# S1C31D50 register map
Vendor: Epson; Series: S1C31D50; File version: 1.00
CPU: CM0PLUS r0p1, little endian, MPU, no FPU, VTOR, 2 interrupt priority bits
Registers are 16-bit, read-write, reset 0x0 unless marked. A register's access mark holds for its fields unless they carry their own. Offsets are from the block's base; [hi:lo] are bit positions; lines under a group give offsets from that group; {n}, {i} and the like mark numbered series; 'fields as' and 'values as' point back to an identical list.

## PPORT — I/O P0-9,PA,PD Ports control
Base 0x00200200
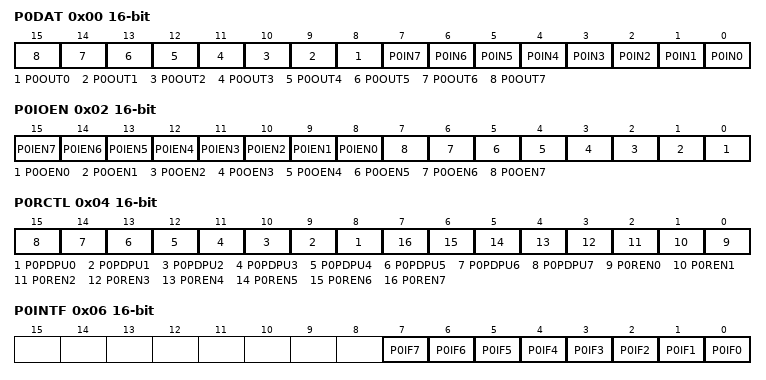
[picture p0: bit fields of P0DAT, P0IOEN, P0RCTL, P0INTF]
0x00 P0DAT — P0 Port Data Register
  [n+8] P0OUT{n} (n=0..7) — P{n:02} port output data
    0=L (Output low level from the port pin); 1=H (Output high level from the port pin)
  [n] P0IN{n} ro (n=0..7) — P{n:02} port input data
    0=L (Port pin = Low level); 1=H (Port pin = High level)
0x02 P0IOEN — P0 Port Enable Register
  [n+8] P0IEN{n} (n=0..7) — P{n:02} port input enable control
    0=DISABLE (Disable (Input data is fixed at 0)); 1=ENABLE (Enable (The port pin status is input))
  [n] P0OEN{n} (n=0..7) — P{n:02} port output enable control
    0=DISABLE (Disable (The port is placed into Hi-Z)); 1=ENABLE (Enable (Data is output from the port pin))
0x04 P0RCTL — P0 Port Pull-up/down Control Register
  [n+8] P0PDPU{n} (n=0..7) — P{n:02} port input resistor select
    0=DOWN (Pull-down resistor); 1=UP (Pull-up resistor)
  [n] P0REN{n} (n=0..7) — P{n:02} port input resistor enable
    0=DISABLE (Disable (No pull-up/down control is performed)); 1=ENABLE (Enable (The built-in pull-up/down resistor is used))
0x06 P0INTF — P0 Port Interrupt Flag Register
  [all] fields
    0=NOT_OCCURED (No cause of interrupt occurred); 1=OCCURED (Cause of interrupt occurred)
  [n] P0IF{n} write-1-clears (n=0..7) — P{n:02} port interrupt flag
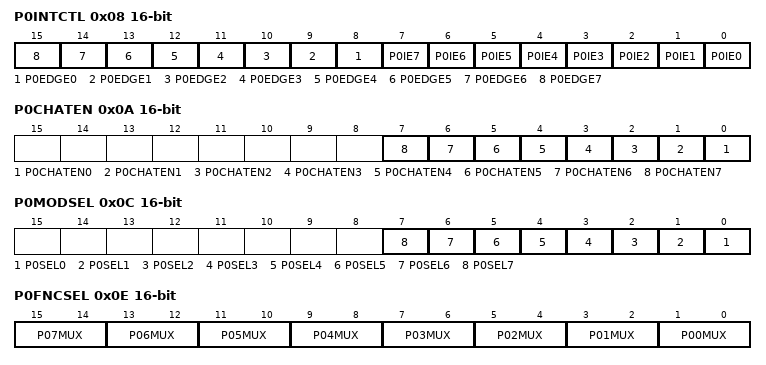
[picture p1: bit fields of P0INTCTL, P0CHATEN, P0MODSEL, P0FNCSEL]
0x08 P0INTCTL — P0 Port Interrupt Control Register
  [n+8] P0EDGE{n} (n=0..7) — P{n:02} port interrupt trigger edge select
    0=POSEDGE (An interrupt will occur at a rising edge); 1=NEGEDGE (An interrupt will occur at a falling edge)
  [n] P0IE{n} (n=0..7) — P{n:02} port interrupt enable
    0=DISABLE (Disable interrupt); 1=ENABLE (Enable interrupt)
0x0A P0CHATEN — P0 Port Chattering Filter Enable Register
  [all] fields
    0=DISABLE (Disable (The chattering filter is bypassed)); 1=ENABLE (Enable (The chattering filter is used))
  [n] P0CHATEN{n} (n=0..7) — P{n:02} chatter less enable
0x0C P0MODSEL — P0 Port Mode Select Register
  [all] fields
    0=PPORT (Use GPIO function); 1=OTHER (Use peripheral I/O function)
  [n] P0SEL{n} (n=0..7) — P{n:02} port mode select
0x0E P0FNCSEL — P0 Port Function Select Register
  [all] fields
    0=FUNC_0 (Function 0); 1=FUNC_1 (Function 1); 2=AIN (Analogue function); 3=LCD_DR (LCD drive function)
  [2n+1:2n] P{n:02}MUX (n=0..7) — P{n:02} port function select
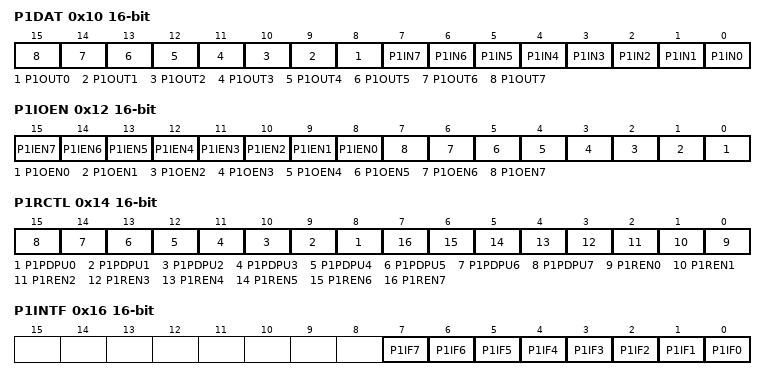
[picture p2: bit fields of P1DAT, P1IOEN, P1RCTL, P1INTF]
0x10 P1DAT — P1 Port Data Register
  [n+8] P1OUT{n} (n=0..7) — P{n+10} port output data
    values as P0DAT.P0OUT0
  [n] P1IN{n} ro (n=0..7) — P{n+10} port input data
    0=L (Port pin = Low level); 1=H (Port pin = High level)
0x12 P1IOEN — P1 Port Enable Register
  [n+8] P1IEN{n} (n=0..7) — P{n+10} port input enable control
    values as P0IOEN.P0IEN0
  [n] P1OEN{n} (n=0..7) — P{n+10} port output enable control
    values as P0IOEN.P0OEN0
0x14 P1RCTL — P1 Port Pull-up/down Control Register
  [n+8] P1PDPU{n} (n=0..7) — P{n+10} port input resistor select
    0=DOWN (Pull-down resistor); 1=UP (Pull-up resistor)
  [n] P1REN{n} (n=0..7) — P{n+10} port input resistor enable
    values as P0RCTL.P0REN0
0x16 P1INTF — P1 Port Interrupt Flag Register
  [all] fields
    values as the fields of P0INTF
  [n] P1IF{n} write-1-clears (n=0..7) — P{n+10} port interrupt flag
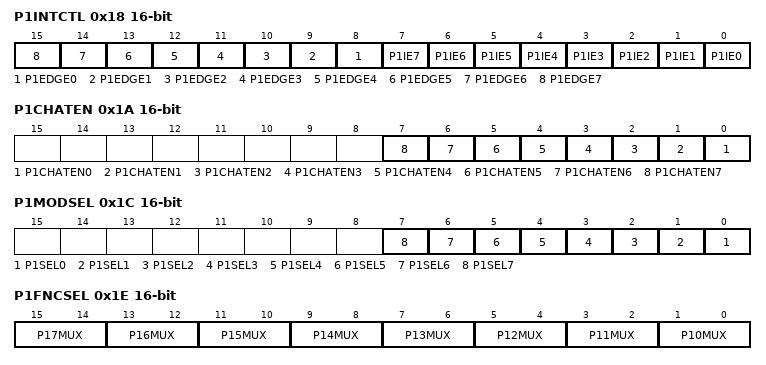
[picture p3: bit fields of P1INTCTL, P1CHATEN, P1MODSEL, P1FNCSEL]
0x18 P1INTCTL — P1 Port Interrupt Control Register
  [n+8] P1EDGE{n} (n=0..7) — P{n+10} port interrupt trigger edge select
    values as P0INTCTL.P0EDGE0
  [n] P1IE{n} (n=0..7) — P{n+10} port interrupt enable
    0=DISABLE (Disable interrupt); 1=ENABLE (Enable interrupt)
0x1A P1CHATEN — P1 Port Chattering Filter Enable Register
  [all] fields
    values as the fields of P0CHATEN
  [n] P1CHATEN{n} (n=0..7) — P{n+10} chatter less enable
0x1C P1MODSEL — P1 Port Mode Select Register
  [all] fields
    values as the fields of P0MODSEL
  [n] P1SEL{n} (n=0..7) — P{n+10} port mode select
0x1E P1FNCSEL — P1 Port Function Select Register
  [all] fields
    values as the fields of P0FNCSEL
  [2n-19:2n-20] P{n}MUX (n=10..17) — P{n} port function select
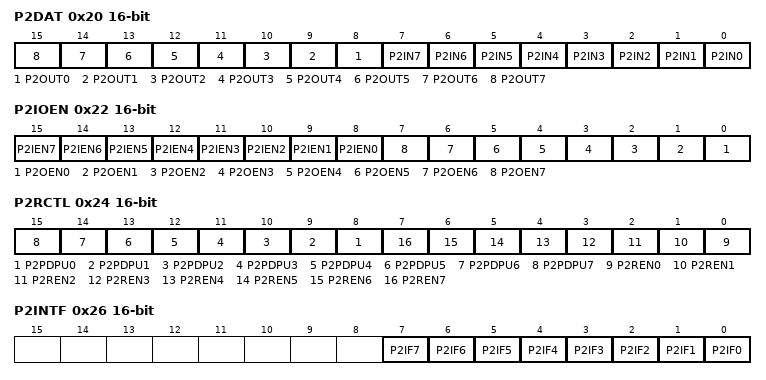
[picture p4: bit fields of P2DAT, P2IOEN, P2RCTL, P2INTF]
0x20 P2DAT — P2 Port Data Register
  [n+8] P2OUT{n} (n=0..7) — P{n+20} port output data
    values as P0DAT.P0OUT0
  [n] P2IN{n} ro (n=0..7) — P{n+20} port input data
    0=L (Port pin = Low level); 1=H (Port pin = High level)
0x22 P2IOEN — P2 Port Enable Register
  [n+8] P2IEN{n} (n=0..7) — P{n+20} port input enable control
    values as P0IOEN.P0IEN0
  [n] P2OEN{n} (n=0..7) — P{n+20} port output enable control
    values as P0IOEN.P0OEN0
0x24 P2RCTL — P2 Port Pull-up/down Control Register
  [n+8] P2PDPU{n} (n=0..7) — P{n+20} port input resistor select
    0=DOWN (Pull-down resistor); 1=UP (Pull-up resistor)
  [n] P2REN{n} (n=0..7) — P{n+20} port input resistor enable
    values as P0RCTL.P0REN0
0x26 P2INTF — P2 Port Interrupt Flag Register
  [all] fields
    values as the fields of P0INTF
  [n] P2IF{n} write-1-clears (n=0..7) — P{n+20} port interrupt flag
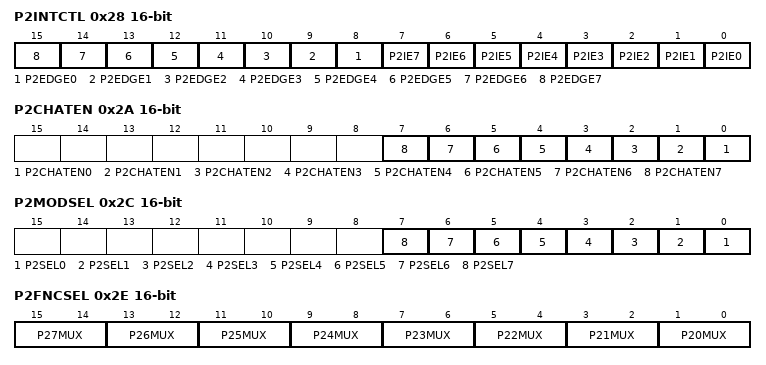
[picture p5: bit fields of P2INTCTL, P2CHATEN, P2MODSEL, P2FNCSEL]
0x28 P2INTCTL — P2 Port Interrupt Control Register
  [n+8] P2EDGE{n} (n=0..7) — P{n+20} port interrupt trigger edge select
    values as P0INTCTL.P0EDGE0
  [n] P2IE{n} (n=0..7) — P{n+20} port interrupt enable
    0=DISABLE (Disable interrupt); 1=ENABLE (Enable interrupt)
0x2A P2CHATEN — P2 Port Chattering Filter Enable Register
  [all] fields
    values as the fields of P0CHATEN
  [n] P2CHATEN{n} (n=0..7) — P{n+20} chatter less enable
0x2C P2MODSEL — P2 Port Mode Select Register
  [all] fields
    values as the fields of P0MODSEL
  [n] P2SEL{n} (n=0..7) — P{n+20} port mode select
0x2E P2FNCSEL — P2 Port Function Select Register
  [all] fields
    values as the fields of P0FNCSEL
  [2n-39:2n-40] P{n}MUX (n=20..27) — P{n} port function select
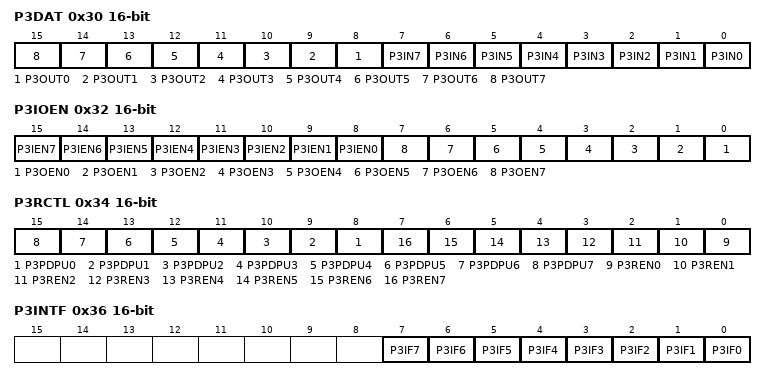
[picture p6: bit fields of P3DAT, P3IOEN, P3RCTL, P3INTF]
0x30 P3DAT — P3 Port Data Register
  [n+8] P3OUT{n} (n=0..7) — P{n+30} port output data
    values as P0DAT.P0OUT0
  [n] P3IN{n} ro (n=0..7) — P{n+30} port input data
    0=L (Port pin = Low level); 1=H (Port pin = High level)
0x32 P3IOEN — P3 Port Enable Register
  [n+8] P3IEN{n} (n=0..7) — P{n+30} port input enable control
    values as P0IOEN.P0IEN0
  [n] P3OEN{n} (n=0..7) — P{n+30} port output enable control
    values as P0IOEN.P0OEN0
0x34 P3RCTL — P3 Port Pull-up/down Control Register
  [n+8] P3PDPU{n} (n=0..7) — P{n+30} port input resistor select
    0=DOWN (Pull-down resistor); 1=UP (Pull-up resistor)
  [n] P3REN{n} (n=0..7) — P{n+30} port input resister enable
    values as P0RCTL.P0REN0
0x36 P3INTF — P3 Port Interrupt Flag Register
  [all] fields
    values as the fields of P0INTF
  [n] P3IF{n} write-1-clears (n=0..7) — P{n+30} port interrupt flag
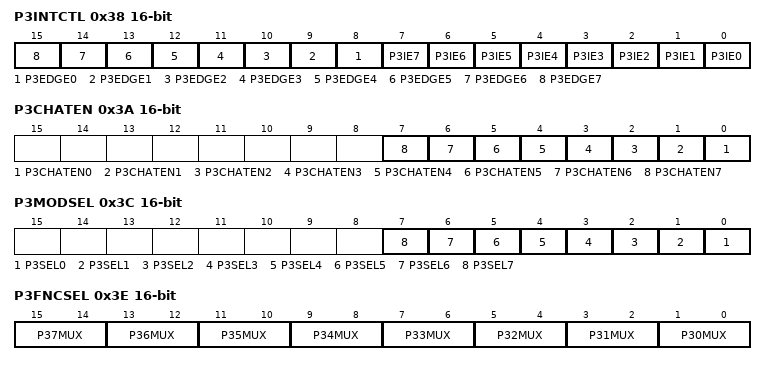
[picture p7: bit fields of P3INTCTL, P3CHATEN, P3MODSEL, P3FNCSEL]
0x38 P3INTCTL — P3 Port Interrupt Control Register
  [n+8] P3EDGE{n} (n=0..7) — P{n+30} port interrupt trigger edge select
    values as P0INTCTL.P0EDGE0
  [n] P3IE{n} (n=0..7) — P{n+30} port interrupt enable
    0=DISABLE (Disable interrupt); 1=ENABLE (Enable interrupt)
0x3A P3CHATEN — P3 Port Chattering Filter Enable Register
  [all] fields
    values as the fields of P0CHATEN
  [n] P3CHATEN{n} (n=0..7) — P{n+30} chatter less enable
0x3C P3MODSEL — P3 Port Mode Select Register
  [all] fields
    values as the fields of P0MODSEL
  [n] P3SEL{n} (n=0..7) — P{n+30} port mode select
0x3E P3FNCSEL — P3 Port Function Select Register
  [all] fields
    values as the fields of P0FNCSEL
  [2n-59:2n-60] P{n}MUX (n=30..37) — P{n} port function select
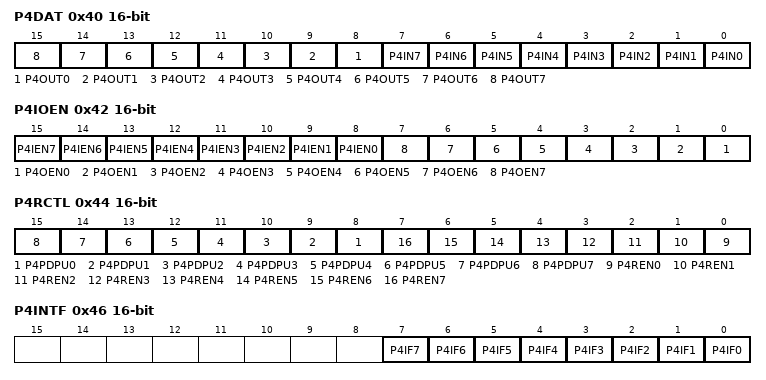
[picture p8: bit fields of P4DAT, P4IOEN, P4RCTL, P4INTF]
0x40 P4DAT — P4 Port Data Register
  [n+8] P4OUT{n} (n=0..7) — P{n+40} port output data
    values as P0DAT.P0OUT0
  [n] P4IN{n} ro (n=0..7) — P{n+40} port input data
    0=L (Port pin = Low level); 1=H (Port pin = High level)
0x42 P4IOEN — P4 Port Enable Register
  [n+8] P4IEN{n} (n=0..7) — P{n+40} port input enable control
    values as P0IOEN.P0IEN0
  [n] P4OEN{n} (n=0..7) — P{n+40} port output enable control
    values as P0IOEN.P0OEN0
0x44 P4RCTL — P4 Port Pull-up/down Control Register
  [n+8] P4PDPU{n} (n=0..7) — P{n+40} port input resistor select
    0=DOWN (Pull-down resistor); 1=UP (Pull-up resistor)
  [n] P4REN{n} (n=0..7) — P{n+40} port input resistor enable
    values as P0RCTL.P0REN0
0x46 P4INTF — P4 Port interrupt Flag Register
  [all] fields
    values as the fields of P0INTF
  [n] P4IF{n} write-1-clears (n=0..7) — P{n+40} port interrupt flag
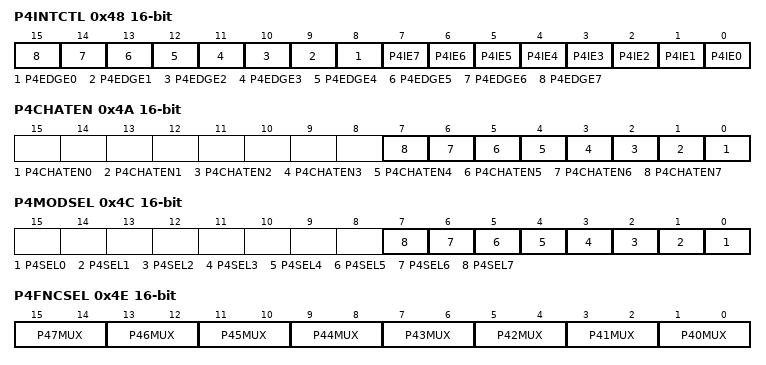
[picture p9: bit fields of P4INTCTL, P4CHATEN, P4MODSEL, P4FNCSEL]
0x48 P4INTCTL — P4 Port Interrupt Control Register
  [n+8] P4EDGE{n} (n=0..7) — P{n+40} port interrupt trigger edge select
    values as P0INTCTL.P0EDGE0
  [n] P4IE{n} (n=0..7) — P{n+40} port interrupt enable
    0=DISABLE (Disable interrupt); 1=ENABLE (Enable interrupt)
0x4A P4CHATEN — P4 Port Chattering Filter Enable Register
  [all] fields
    values as the fields of P0CHATEN
  [n] P4CHATEN{n} (n=0..7) — P{n+40} chatter less enable
0x4C P4MODSEL — P4 Port Mode Select Register
  [all] fields
    values as the fields of P0MODSEL
  [n] P4SEL{n} (n=0..7) — P{n+40} port mode select
0x4E P4FNCSEL — P4 Port Function Select Register
  [all] fields
    values as the fields of P0FNCSEL
  [2n-79:2n-80] P{n}MUX (n=40..47) — P{n} port function select
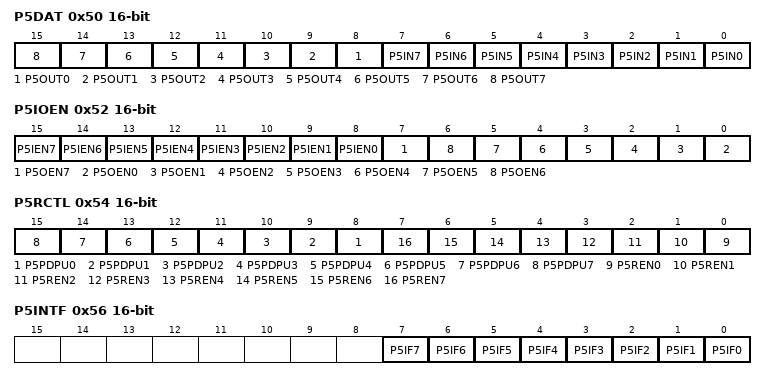
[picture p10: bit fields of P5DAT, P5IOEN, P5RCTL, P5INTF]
0x50 P5DAT — P5 Port Data Register
  [n+8] P5OUT{n} (n=0..7) — P{n+50} port output data
    values as P0DAT.P0OUT0
  [n] P5IN{n} ro (n=0..7) — P{n+50} port input data
    0=L (Port pin = Low level); 1=H (Port pin = High level)
0x52 P5IOEN — P5 Port Enable Register
  [n+8] P5IEN{n} (n=0..7) — P{n+50} port input enable control
    values as P0IOEN.P0IEN0
  [7] P5OEN7 — P57port output enable control
    values as P0IOEN.P0OEN0
  [n] P5OEN{n} (n=0..6) — P{n+50} port output enable control
    values as P0IOEN.P0OEN0
0x54 P5RCTL — P5 Port Pull-up/down Control Register
  [n+8] P5PDPU{n} (n=0..7) — P{n+50} port input resistor select
    0=DOWN (Pull-down resistor); 1=UP (Pull-up resistor)
  [n] P5REN{n} (n=0..7) — P{n+50} port input resistor enable
    values as P0RCTL.P0REN0
0x56 P5INTF — P5 Port Interrupt Flag Register
  [all] fields
    values as the fields of P0INTF
  [n] P5IF{n} write-1-clears (n=0..7) — P{n+50} port interrupt flag
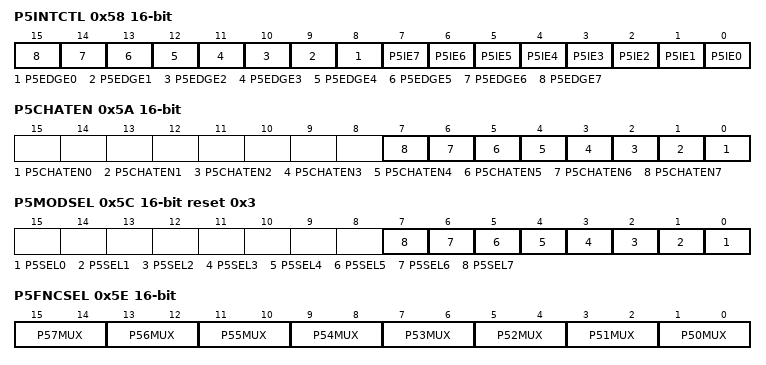
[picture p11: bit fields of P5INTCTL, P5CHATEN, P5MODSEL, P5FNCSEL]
0x58 P5INTCTL — P5 Port Interrupt Control Register
  [n+8] P5EDGE{n} (n=0..7) — P{n+50} port interrupt trigger edge select
    values as P0INTCTL.P0EDGE0
  [n] P5IE{n} (n=0..7) — P{n+50} port interrupt enable
    0=DISABLE (Disable interrupt); 1=ENABLE (Enable interrupt)
0x5A P5CHATEN — P5 Port Chattering Filter Enable Register
  [all] fields
    values as the fields of P0CHATEN
  [n] P5CHATEN{n} (n=0..7) — P{n+50} chatter less enable
0x5C P5MODSEL reset 0x3 — P5 Port Mode Select Register
  [all] fields
    values as the fields of P0MODSEL
  [n] P5SEL{n} (n=0..7) — P{n+50} port mode select
0x5E P5FNCSEL — P5 Port Function Select Register
  [all] fields
    values as the fields of P0FNCSEL
  [2n-99:2n-100] P{n}MUX (n=50..57) — P{n} port function select
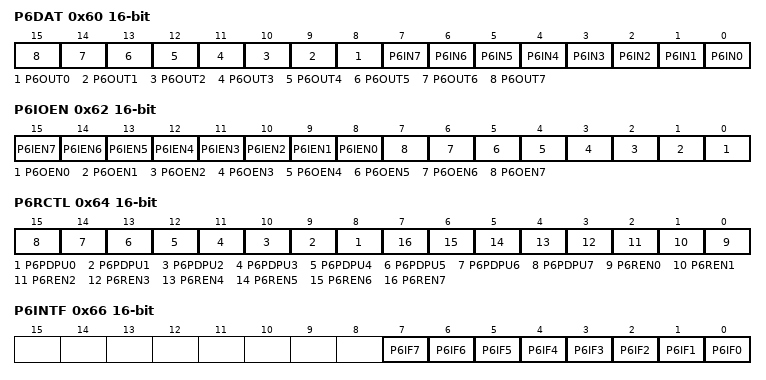
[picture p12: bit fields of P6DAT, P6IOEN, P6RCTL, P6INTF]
0x60 P6DAT — P6 Port Data Register
  [n+8] P6OUT{n} (n=0..7) — P{n+60} port output data
    values as P0DAT.P0OUT0
  [n] P6IN{n} ro (n=0..7) — P{n+60} port input data
    0=L (Port pin = Low level); 1=H (Port pin = High level)
0x62 P6IOEN — P6 Port Enable Register
  [n+8] P6IEN{n} (n=0..7) — P{n+60} port input enable control
    values as P0IOEN.P0IEN0
  [n] P6OEN{n} (n=0..7) — P{n+60} port output enable control
    values as P0IOEN.P0OEN0
0x64 P6RCTL — P6 Port Pull-up/down Control Register
  [n+8] P6PDPU{n} (n=0..7) — P{n+60} port input resistor select
    0=DOWN (Pull-down resistor); 1=UP (Pull-up resistor)
  [n] P6REN{n} (n=0..7) — P{n+60} port input resistor enable
    values as P0RCTL.P0REN0
0x66 P6INTF — P6 Port Interrupt Flag Register
  [all] fields
    values as the fields of P0INTF
  [n] P6IF{n} write-1-clears (n=0..7) — P{n+60} port interrupt flag
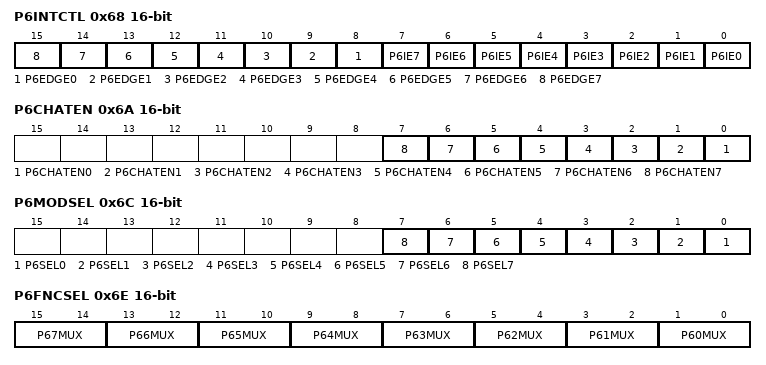
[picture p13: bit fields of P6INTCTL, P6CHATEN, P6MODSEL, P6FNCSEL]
0x68 P6INTCTL — P6 Port Interrupt Control Register
  [n+8] P6EDGE{n} (n=0..7) — P{n+60} port interrupt trigger edge select
    values as P0INTCTL.P0EDGE0
  [n] P6IE{n} (n=0..7) — P{n+60} port interrupt enable
    0=DISABLE (Disable interrupt); 1=ENABLE (Enable interrupt)
0x6A P6CHATEN — P6 Port Chattering Filter Enable Register
  [all] fields
    values as the fields of P0CHATEN
  [n] P6CHATEN{n} (n=0..7) — P{n+60} chatter less enable
0x6C P6MODSEL — P6 Port Mode Select Register
  [all] fields
    values as the fields of P0MODSEL
  [n] P6SEL{n} (n=0..7) — P{n+60} port mode select
0x6E P6FNCSEL — P6 Port Function Select Register
  [all] fields
    values as the fields of P0FNCSEL
  [2n-119:2n-120] P{n}MUX (n=60..67) — P{n} port function select
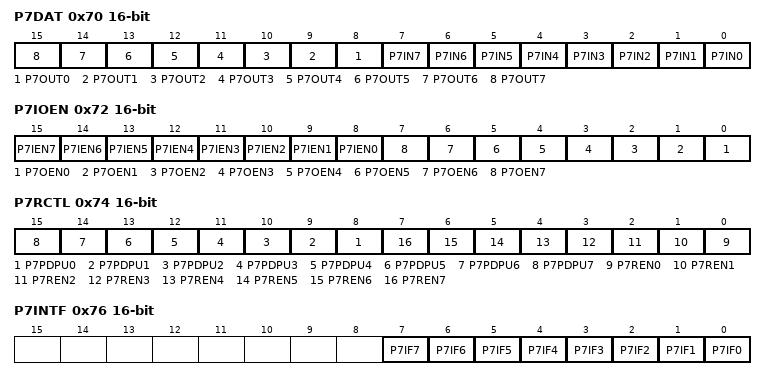
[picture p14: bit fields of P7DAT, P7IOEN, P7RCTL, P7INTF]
0x70 P7DAT — P7 Port Data Register
  [n+8] P7OUT{n} (n=0..7) — P{n+70} port output data
    values as P0DAT.P0OUT0
  [n] P7IN{n} ro (n=0..7) — P{n+70} port input data
    0=L (Port pin = Low level); 1=H (Port pin = High level)
0x72 P7IOEN — P7 Port Enable Register
  [n+8] P7IEN{n} (n=0..7) — P{n+70} port input enable control
    values as P0IOEN.P0IEN0
  [n] P7OEN{n} (n=0..7) — P{n+70} port output enable control
    values as P0IOEN.P0OEN0
0x74 P7RCTL — P7 Port Pull-up/down Control Register
  [n+8] P7PDPU{n} (n=0..7) — P{n+70} port input resistor select
    0=DOWN (Pull-down resistor); 1=UP (Pull-up resistor)
  [n] P7REN{n} (n=0..7) — P{n+70} port input resistor enable
    values as P0RCTL.P0REN0
0x76 P7INTF — P7 Port Interrupt Flag Register
  [all] fields
    values as the fields of P0INTF
  [n] P7IF{n} write-1-clears (n=0..7) — P{n+70} port interrupt flag
0x78 P7INTCTL — P7 Port Interrupt Control Register
  [n+8] P7EDGE{n} (n=0..7) — P{n+70} port interrupt trigger edge select
    values as P0INTCTL.P0EDGE0
  [n] P7IE{n} (n=0..7) — P{n+70} port interrupt enable
    0=DISABLE (Disable interrupt); 1=ENABLE (Enable interrupt)
0x7A P7CHATEN — P7 Port Chattering Filter Enable Register
  [all] fields
    values as the fields of P0CHATEN
  [n] P7CHATEN{n} (n=0..7) — P{n+70} chatter less enable
0x7C P7MODSEL — P7 Port Mode Select Register
  [all] fields
    values as the fields of P0MODSEL
  [n] P7SEL{n} (n=0..7) — P{n+70} port mode select
0x7E P7FNCSEL — P7 Port Function Select Register
  [all] fields
    values as the fields of P0FNCSEL
  [2n-139:2n-140] P{n}MUX (n=70..77) — P{n} port function select
0x80 P8DAT — P8 Port Data Register
  [n+8] P8OUT{n} (n=0..7) — P{n+80} port output data
    values as P0DAT.P0OUT0
  [n] P8IN{n} ro (n=0..7) — P{n+80} port input data
    0=L (Port pin = Low level); 1=H (Port pin = High level)
0x82 P8IOEN — P8 Port Enable Register
  [n+8] P8IEN{n} (n=0..7) — P{n+80} port input enable control
    values as P0IOEN.P0IEN0
  [n] P8OEN{n} (n=0..7) — P{n+80} port output enable control
    values as P0IOEN.P0OEN0
0x84 P8RCTL — P8 Port Pull-up/down Control Register
  [n+8] P8PDPU{n} (n=0..7) — P{n+80} port input resistor select
    0=DOWN (Pull-down resistor); 1=UP (Pull-up resistor)
  [n] P8REN{n} (n=0..7) — P{n+80} port input resistor enable
    values as P0RCTL.P0REN0
0x86 P8INTF — P8 Port Interrupt Flag Register
  [all] fields
    values as the fields of P0INTF
  [n] P8IF{n} write-1-clears (n=0..7) — P{n+80} port interrupt flag
0x88 P8INTCTL — P8 Port Interrupt Control Register
  [n+8] P8EDGE{n} (n=0..7) — P{n+80} port interrupt trigger edge select
    values as P0INTCTL.P0EDGE0
  [n] P8IE{n} (n=0..7) — P{n+80} port interrupt enable
    0=DISABLE (Disable interrupt); 1=ENABLE (Enable interrupt)
0x8A P8CHATEN — P8 Port Chattering Filter Enable Register
  [all] fields
    values as the fields of P0CHATEN
  [n] P8CHATEN{n} (n=0..7) — P{n+80} chatter less enable
0x8C P8MODSEL — P8 Port Mode Select Register
  [all] fields
    values as the fields of P0MODSEL
  [n] P8SEL{n} (n=0..7) — P{n+80} port mode select
0x8E P8FNCSEL — P8 Port Function Select Register
  [all] fields
    values as the fields of P0FNCSEL
  [2n-159:2n-160] P{n}MUX (n=80..87) — P{n} port function select
0x90 P9DAT — P9 Port Data Register
  [n+8] P9OUT{n} (n=0..5) — P{n+90} port output data
    values as P0DAT.P0OUT0
  [n] P9IN{n} ro (n=0..5) — P{n+90} port input data
    0=L (Port pin = Low level); 1=H (Port pin = High level)
0x92 P9IOEN — P9 Port Enable Register
  [n+8] P9IEN{n} (n=0..5) — P{n+90} port input enable control
    values as P0IOEN.P0IEN0
  [n] P9OEN{n} (n=0..5) — P{n+90} port output enable control
    values as P0IOEN.P0OEN0
0x94 P9RCTL — P9 Port Pull-up/down Control Register
  [n+8] P9PDPU{n} (n=0..5) — P{n+90} port input resistor select
    0=DOWN (Pull-down resistor); 1=UP (Pull-up resistor)
  [n] P9REN{n} (n=0..5) — P{n+90} port input resistor enable
    values as P0RCTL.P0REN0
0x96 P9INTF — P9 Port Interrupt Flag Register
  [all] fields
    values as the fields of P0INTF
  [n] P9IF{n} write-1-clears (n=0..5) — P{n+90} port interrupt flag
0x98 P9INTCTL — P9 Port Interrupt Control Register
  [n+8] P9EDGE{n} (n=0..5) — P{n+90} port interrupt trigger edge select
    values as P0INTCTL.P0EDGE0
  [n] P9IE{n} (n=0..5) — P{n+90} port interrupt enable
    0=DISABLE (Disable interrupt); 1=ENABLE (Enable interrupt)
0x9A P9CHATEN — P9 Port Chattering Filter Enable Register
  [all] fields
    values as the fields of P0CHATEN
  [n] P9CHATEN{n} (n=0..5) — P{n+90} chatter less enable
0x9C P9MODSEL — P9 Port Mode Select Register
  [all] fields
    values as the fields of P0MODSEL
  [n] P9SEL{n} (n=0..5) — P{n+90} port mode select
0x9E P9FNCSEL — P9 Port Function Select Register
  [all] fields
    values as the fields of P0FNCSEL
  [2n-179:2n-180] P{n}MUX (n=90..95) — P{n} port function select
0xA0 PADAT — PA Port Data Register
  [n+8] PAOUT{n} (n=0..6) — PA{n} port output data
    values as P0DAT.P0OUT0
  [n] PAIN{n} ro (n=0..6) — PA{n} port input data
    0=L (Port pin = Low level); 1=H (Port pin = High level)
0xA2 PAIOEN — PA Port Enable Register
  [n+8] PAIEN{n} (n=0..6) — PA{n} port input enable control
    values as P0IOEN.P0IEN0
  [n] PAOEN{n} (n=0..6) — PA{n} port output enable control
    values as P0IOEN.P0OEN0
0xA4 PARCTL — PA Port Pull-up/down Control Register
  [n+8] PAPDPU{n} (n=0..6) — PA{n} port input resistor select
    0=DOWN (Pull-down resistor); 1=UP (Pull-up resistor)
  [n] PAREN{n} (n=0..6) — PA{n} port input resistor enable
    values as P0RCTL.P0REN0
0xA6 PAINTF — PA Port Interrupt Flag Register
  [all] fields
    values as the fields of P0INTF
  [n] PAIF{n} write-1-clears (n=0..6) — PA{n} port interrupt flag
0xA8 PAINTCTL — PA Port Interrupt Control Register
  [n+8] PAEDGE{n} (n=0..6) — PA{n} port interrupt trigger edge select
    values as P0INTCTL.P0EDGE0
  [n] PAIE{n} (n=0..6) — PA{n} port interrupt enable
    0=DISABLE (Disable interrupt); 1=ENABLE (Enable interrupt)
0xAA PACHATEN — PA Port Chattering Filter Enable Register
  [all] fields
    values as the fields of P0CHATEN
  [n] PACHATEN{n} (n=0..6) — PA{n} chatter less enable
0xAC PAMODSEL — PA Port Mode Select Register
  [all] fields
    values as the fields of P0MODSEL
  [n] PASEL{n} (n=0..6) — PA{n} port mode select
0xAE PAFNCSEL — PA Port Function Select Register
  [all] fields
    values as the fields of P0FNCSEL
  [2n+1:2n] PA{n}MUX (n=0..6) — PA{n} port function select
0xD0 PDDAT — PD Port Data Register
  [n+8] PDOUT{n} (n=0..5) — PD{n} port output data
    values as P0DAT.P0OUT0
  [n] PDIN{n} ro (n=0..5) — PD{n} port input data
    0=L (Port pin = Low level); 1=H (Port pin = High level)
0xD2 PDIOEN — PD Port Enable Register
  [n+8] PDIEN{n} (n=0..5) — PD{n} port input enable control
    values as P0IOEN.P0IEN0
  [n] PDOEN{n} (n=0..5) — PD{n} port output enable control
    values as P0IOEN.P0OEN0
0xD4 PDRCTL — PD Port Pull-up/down Control Register
  [n+8] PDPDPU{n} (n=0..5) — PD{n} port input resistor select
    0=DOWN (Pull-down resistor); 1=UP (Pull-up resistor)
  [n] PDREN{n} (n=0..5) — PD{n} port input resistor enable
    values as P0RCTL.P0REN0
0xDC PDMODSEL reset 0x3 — PD Port Mode Select Register
  [all] fields
    values as the fields of P0MODSEL
  [n] PDSEL{n} (n=0..5) — PD{n} port mode select
0xDE PDFNCSEL — PD Port Function Select Register
  [all] fields
    values as the fields of P0FNCSEL
  [2n+1:2n] PD{n}MUX (n=2..5) — PD{n} port function select
  [3:2] PD1MUX ro — PD1 port function select
  [1:0] PD0MUX ro — PD0 port function select
0xE0 CLK — P Port Clock Control Register
  [8] DBRUN — Enable clock on debug mode (can be write protected)
    0=DISABLE; 1=ENABLE
  [7:4] CLKDIV — Clock division select for chattering filter clock (can be write protected)
  [1:0] CLKSRC — Clock source select for chattering filter clock (can be write protected)
    0=IOSC; 1=OSC1; 2=OSC3; 3=EXOSC
0xE2 INTFGRP ro — P Port Interrupt Flag Group Register
  [all] fields
    0=NOT_OCCURED (No port generated an interrupt); 1=OCCURED (Port generated an interrupt)
  [10] PAINT — PA port group interrupt flag
  [n] P{n}INT (n=0..9) — P{n} port group interrupt flag
